# CPU_ROM_TABLE register map
Vendor: Texas Instruments
Peripheral module from a debugger description file (folder CC23x0R5).
Registers are 32-bit, read-only, reset 0x0 unless marked. A register's access mark holds for its fields unless they carry their own. Offsets are as the file gives them; lines under a group give offsets from that group; [hi:lo] are bit positions; {n}, {i} and the like mark numbered series; 'fields as' and 'values as' point back to an identical list; <NAME> marks a mode.

## CPU_ROM_TABLE
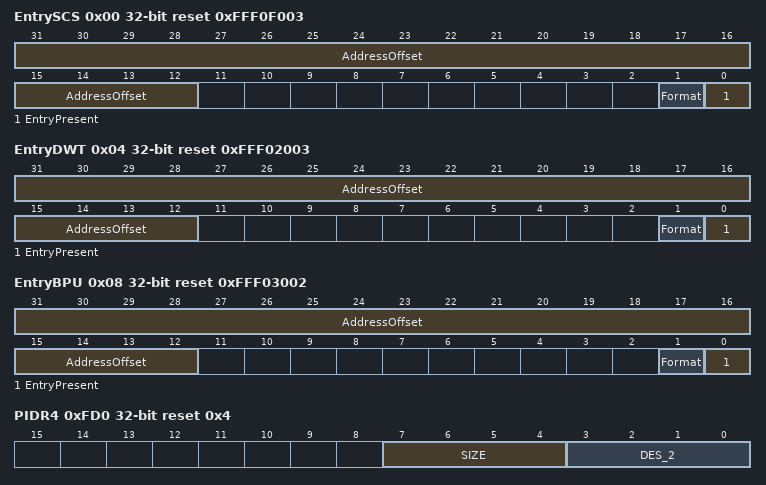
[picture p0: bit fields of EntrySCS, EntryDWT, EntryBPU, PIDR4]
0x00 EntrySCS reset 0xFFF0F003 — ROM Table Entry Points to the System Control Space (SCS) at 0xE000E000. This includes core debug control registers.
  [31:12] AddressOffset — Base address of the highest 4KB block for the component, relative to the ROM address.
  [1] Format — Base address of the highest 4KB block for the component, relative to the ROM address.
  [0] EntryPresent — This bit indicates whether an entry is present at this location in the ROM table. 0x0:Rom table entry is not present and must be skipped. 0x1:Rom table entry is present.
0x04 EntryDWT reset 0xFFF02003 — ROM Table Entry Points to the DW unit at 0xE0001000.
  fields as EntrySCS
0x08 EntryBPU reset 0xFFF03002 — ROM Table Entry Points to the BPU at 0xE0002000.
  fields as EntrySCS
0x0C EntryEnd — ROM Table Entry Marks of end of table.
  [31:0] END — Blank ROM Table entry indicating the end of the ROM Table content.
0xFCC MEMTYPE reset 0x1 — MEMTYPE Register Identifies the type of memory present on the bus that connects the DAP to the ROM Table.
  [0] SYSMEM — System memory present. Indicates whether system memory is present on the bus that connects to the ROM table. 0x0:System memory not present on bus. this is a dedicated debug bus. 0x1:System memory is present on bus.
0xFD0 PIDR4 reset 0x4 — Peripheral ID Register 4 Part of the set of Peripheral Identification registers. Contains part of the designer identity and the memory footprint indicator.
  [7:4] SIZE — This is a 4-bit value that indicates the total contiguous size of the memory window used by this component in powers of 2 from the standard 4KB. If a component only requires the standard 4KB then this should read as 0x0, 4KB only, for 8KB set to 0x1, 16KB == 0x2, 32KB == 0x3, and so on.
  [3:0] DES_2 — Number of JEDEC continuation codes. Indicates the designer of the component (along with the identity code)
{0xFC0+4i} PIDR{i} (i=5..7) — Peripheral ID Register {i} Reserved
0xFE0 PIDR0 reset 0xC0 — Peripheral ID Register 0 Part of the set of Peripheral Identification registers. Contains part of the designer specific part number.
  [7:0] PART_0 — Bits [7:0] of the component's part number. This is selected by the designer of the component.
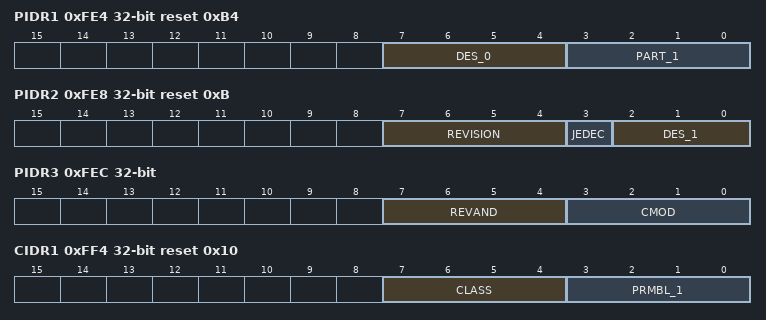
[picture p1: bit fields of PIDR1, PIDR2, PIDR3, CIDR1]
0xFE4 PIDR1 reset 0xB4 — Peripheral ID Register 1 Part of the set of Peripheral Identification registers. Contains part of the designer specific part number and part of the designer identity.
  [7:4] DES_0 — Bits [3:0] of the JEDEC identity code indicating the designer of the component (along with the continuation code)
  [3:0] PART_1 — Bits [11:8] of the component's part number. This is selected by the designer of the component.
0xFE8 PIDR2 reset 0xB — Peripheral ID Register 2 Part of the set of Peripheral Identification registers. Contains part of the designer identity and the product revision.
  [7:4] REVISION — The Revision field is an incremental value starting at 0x0 for the first design of this component. This only increases by 1 for both major and minor revisions and is simply used as a look-up to establish the exact major/minor revision.
  [3] JEDEC — Always set. Indicates that a JEDEC assigned value is used
  [2:0] DES_1 — Bits [6:4] of the JEDEC identity code indicating the designer of the component (along with the continuation code)
0xFEC PIDR3 — Peripheral ID Register 3 Part of the set of Peripheral Identification registers. Contains the RevAnd and Customer Modified fields.
  [7:4] REVAND — This field indicates minor errata fixes specific to this design, for example metal fixes after implementation. In most cases this field is zero. It is recommended that component designers ensure this field can be changed by a metal fix if required, for example by driving it from registers that reset to zero.
  [3:0] CMOD — Where the component is reusable IP, this value indicates if the customer has modified the behavior of the component. In most cases this field is zero.
0xFF0 CIDR0 reset 0xD — Component ID Register 0 A component identification register, that indicates that the identification registers are present.
  [7:0] PRMBL_0 — Contains bits [7:0] of the component identification
0xFF4 CIDR1 reset 0x10 — Component ID Register 1 A component identification register, that indicates that the identification registers are present. This register also indicates the component class.
  [7:4] CLASS — Class of the component. E.g. ROM table, CoreSight component etc. Constitutes bits [15:12] of the component identification.
  [3:0] PRMBL_1 — Contains bits [11:8] of the component identification
0xFF8 CIDR2 reset 0x5 — Component ID Register 2 A component identification register, that indicates that the identification registers are present.
  [7:0] PRMBL_2 — Contains bits [23:16] of the component identification
0xFFC CIDR3 reset 0xB1 — Component ID Register 3 A component identification register, that indicates that the identification registers are present.
  [7:0] PRMBL_3 — Contains bits [31:24] of the component identification
